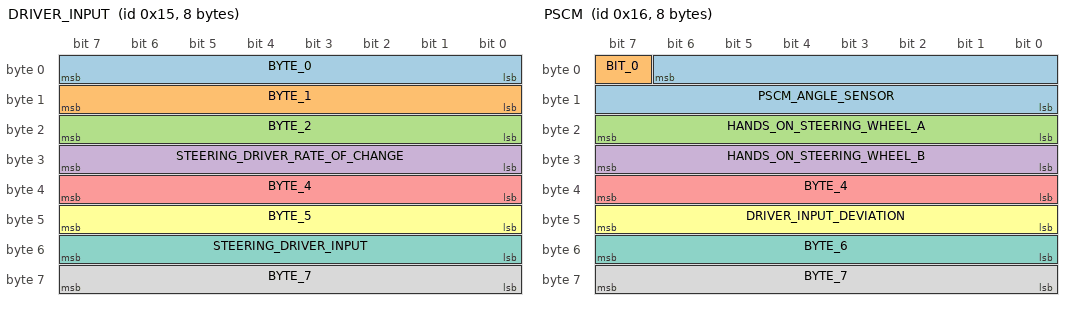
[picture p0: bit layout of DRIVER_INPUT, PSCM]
BO_ 21 DRIVER_INPUT: 8 XXX
 SG_ BYTE_0 : 7|8@0+ (1,0) [0|255] "" XXX
 SG_ BYTE_1 : 15|8@0+ (1,0) [0|255] "" XXX
 SG_ BYTE_2 : 16|8@1+ (1,0) [0|255] "" XXX
 SG_ STEERING_DRIVER_RATE_OF_CHANGE : 31|8@0- (1,0) [0|255] "" XXX
 SG_ BYTE_4 : 39|8@0+ (1,0) [0|255] "" XXX
 SG_ BYTE_5 : 40|8@1+ (1,0) [0|255] "" XXX
 SG_ STEERING_DRIVER_INPUT : 55|8@0- (1,1) [0|255] "" XXX
 SG_ BYTE_7 : 63|8@0+ (1,0) [0|255] "" XXX

BO_ 22 PSCM: 8 XXX
 SG_ PSCM_ANGLE_SENSOR : 6|15@0- (0.05596,0) [-916|916] "º" XXX
 SG_ BIT_0 : 7|1@0+ (1,0) [0|1] "" XXX
 SG_ HANDS_ON_STEERING_WHEEL_A : 23|8@0+ (1,0) [0|255] "" XXX
 SG_ HANDS_ON_STEERING_WHEEL_B : 31|8@0+ (1,0) [0|255] "" XXX
 SG_ BYTE_4 : 39|8@0+ (1,0) [0|255] "" XXX
 SG_ DRIVER_INPUT_DEVIATION : 47|8@0- (1,0) [-128|127] "" XXX
 SG_ BYTE_6 : 55|8@0+ (1,0) [0|255] "" XXX
 SG_ BYTE_7 : 63|8@0+ (1,0) [0|255] "" XXX

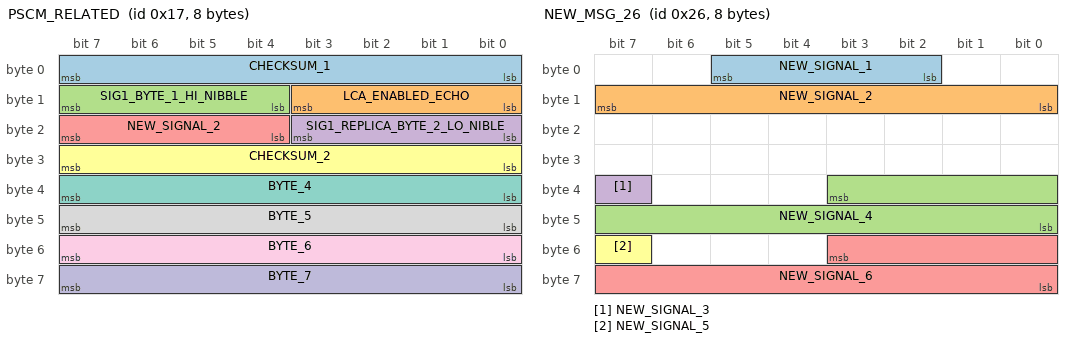
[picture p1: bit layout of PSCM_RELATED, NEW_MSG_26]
BO_ 23 PSCM_RELATED: 8 XXX
 SG_ CHECKSUM_1 : 7|8@0+ (1,0) [0|255] "" XXX
 SG_ LCA_ENABLED_ECHO : 11|4@0+ (1,0) [0|15] "" XXX
 SG_ SIG1_BYTE_1_HI_NIBBLE : 15|4@0+ (1,0) [0|15] "" XXX
 SG_ SIG1_REPLICA_BYTE_2_LO_NIBLE : 19|4@0+ (1,0) [0|15] "" XXX
 SG_ NEW_SIGNAL_2 : 23|4@0+ (1,0) [0|15] "" XXX
 SG_ CHECKSUM_2 : 31|8@0+ (1,0) [0|255] "" XXX
 SG_ BYTE_4 : 39|8@0+ (1,0) [0|255] "" XXX
 SG_ BYTE_5 : 47|8@0+ (1,0) [0|255] "" XXX
 SG_ BYTE_6 : 55|8@0+ (1,0) [0|255] "" XXX
 SG_ BYTE_7 : 63|8@0+ (1,0) [0|255] "" XXX

BO_ 26 NEW_MSG_1A: 8 XXX
 SG_ NEW_SIGNAL_2 : 5|1@0+ (1,0) [0|1] "" XXX
 SG_ NEW_SIGNAL_1 : 7|1@0+ (1,0) [0|1] "" XXX

BO_ 38 NEW_MSG_26: 8 XXX
 SG_ NEW_SIGNAL_1 : 5|4@0+ (1,0) [0|15] "" XXX
 SG_ NEW_SIGNAL_2 : 15|8@0+ (1,0) [0|255] "" XXX
 SG_ NEW_SIGNAL_4 : 35|12@0+ (1,0) [0|4095] "" XXX
 SG_ NEW_SIGNAL_3 : 39|1@0+ (1,0) [0|1] "" XXX
 SG_ NEW_SIGNAL_6 : 51|12@0+ (1,0) [0|4095] "" XXX
 SG_ NEW_SIGNAL_5 : 55|1@0+ (1,0) [0|1] "" XXX

BO_ 55 NEW_MSG_37: 8 XXX
 SG_ ACCELERATOR_PEDAL_RATE_OF_CHANGE : 6|15@0+ (1,0) [0|32767] "" XXX

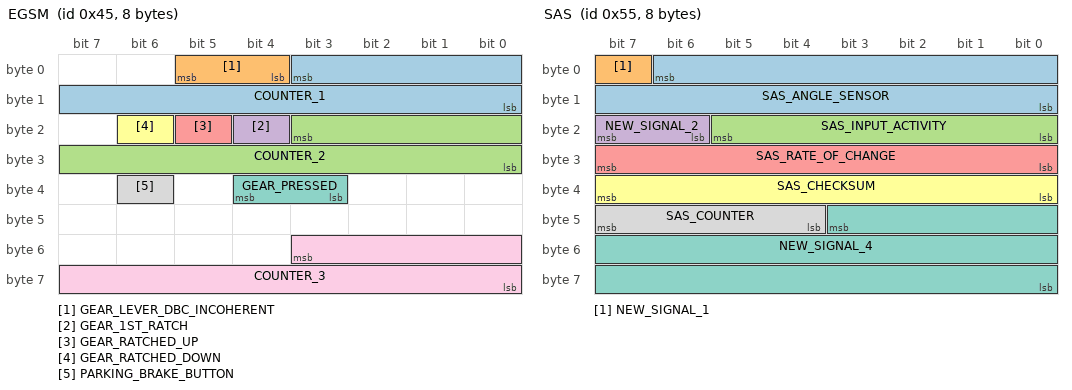
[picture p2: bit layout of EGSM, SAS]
BO_ 69 EGSM: 8 XXX
 SG_ COUNTER_1 : 3|12@0+ (1,0) [0|4095] "" XXX
 SG_ GEAR_LEVER_DBC_INCOHERENT : 5|2@0+ (1,0) [0|3] "" XXX
 SG_ COUNTER_2 : 19|12@0+ (1,0) [0|4095] "" XXX
 SG_ GEAR_1ST_RATCH : 20|1@0+ (1,0) [0|1] "" XXX
 SG_ GEAR_RATCHED_UP : 21|1@0+ (1,0) [0|1] "" XXX
 SG_ GEAR_RATCHED_DOWN : 22|1@0+ (1,0) [0|1] "" XXX
 SG_ GEAR_PRESSED : 36|2@0+ (1,0) [0|3] "" XXX
 SG_ PARKING_BRAKE_BUTTON : 38|1@0+ (1,0) [0|1] "" XXX
 SG_ COUNTER_3 : 51|12@0+ (1,0) [0|4095] "" XXX

BO_ 85 SAS: 8 XXX
 SG_ SAS_ANGLE_SENSOR : 6|15@0- (0.05596,0) [0|32767] "º" XXX
 SG_ NEW_SIGNAL_1 : 7|1@0+ (1,0) [0|1] "" XXX
 SG_ SAS_INPUT_ACTIVITY : 21|6@0+ (1,0) [0|16383] "" XXX
 SG_ NEW_SIGNAL_2 : 23|2@0+ (1,0) [0|3] "" XXX
 SG_ SAS_RATE_OF_CHANGE : 31|8@0- (1,0) [0|255] "" XXX
 SG_ SAS_CHECKSUM : 39|8@0+ (1,0) [0|4095] "" XXX
 SG_ NEW_SIGNAL_4 : 43|20@0+ (1,0) [0|1048575] "" XXX
 SG_ SAS_COUNTER : 44|4@1+ (1,0) [0|15] "" XXX

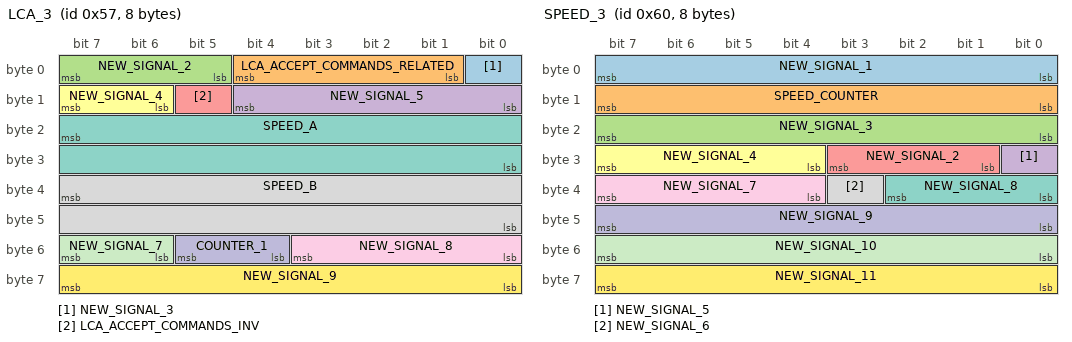
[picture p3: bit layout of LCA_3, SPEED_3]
BO_ 87 LCA_3: 8 XXX
 SG_ NEW_SIGNAL_3 : 0|1@0+ (1,0) [0|1] "" XXX
 SG_ LCA_ACCEPT_COMMANDS_RELATED : 4|4@0+ (1,0) [0|15] "" XXX
 SG_ NEW_SIGNAL_2 : 7|3@0+ (1,0) [0|7] "" XXX
 SG_ NEW_SIGNAL_5 : 12|5@0+ (1,0) [0|31] "" XXX
 SG_ LCA_ACCEPT_COMMANDS_INV : 13|1@0+ (1,0) [0|1] "" XXX
 SG_ NEW_SIGNAL_4 : 15|2@0+ (1,0) [0|3] "" XXX
 SG_ SPEED_A : 23|16@0+ (1,0) [0|65535] "" XXX
 SG_ SPEED_B : 39|16@0+ (1,0) [0|65535] "" XXX
 SG_ NEW_SIGNAL_8 : 51|4@0+ (1,0) [0|15] "" XXX
 SG_ COUNTER_1 : 53|2@0+ (1,0) [0|3] "" XXX
 SG_ NEW_SIGNAL_7 : 55|2@0+ (1,0) [0|3] "" XXX
 SG_ NEW_SIGNAL_9 : 63|8@0+ (1,0) [0|255] "" XXX

BO_ 88 LCA: 8 XXX
 SG_ NEW_SIGNAL_3 : 1|2@0+ (1,0) [0|3] "" XXX
 SG_ NEW_SIGNAL_8 : 2|1@0+ (1,0) [0|1] "" XXX
 SG_ LCA_ENABLE_INV : 3|1@0+ (1,0) [0|1] "" XXX
 SG_ NEW_SIGNAL_2 : 5|2@0+ (1,0) [0|3] "" XXX
 SG_ NEW_SIGNAL_1 : 7|2@0+ (1,0) [0|3] "" XXX
 SG_ LCA_STEER_LOOSELY_1 : 15|8@0+ (1,0) [0|255] "" XXX
 SG_ LCA_STEER_ACTIVE_INCOHERENT : 16|1@0+ (1,0) [0|1] "" XXX
 SG_ LCA_STEER_ACTIVE : 18|2@0+ (1,0) [0|3] "" XXX
 SG_ NEW_SIGNAL_7 : 21|3@0+ (1,0) [0|7] "" XXX
 SG_ NEW_SIGNAL_9 : 23|2@0+ (1,0) [0|3] "" XXX
 SG_ LCA_STEER_LOOSELY_2 : 31|8@0+ (1,0) [0|255] "" XXX
 SG_ NEW_SIGNAL_4 : 39|8@0+ (1,0) [0|255] "" XXX
 SG_ CURVE_RIGHT : 45|6@0+ (1,0) [0|63] "" XXX
 SG_ NEW_SIGNAL_5 : 46|2@1+ (1,0) [0|3] "" XXX
 SG_ LCA_STEER : 55|8@0+ (1,0) [0|255] "" XXX
 SG_ NEW_SIGNAL_10 : 59|4@0+ (1,0) [0|15] "" XXX
 SG_ NEW_SIGNAL_6 : 60|4@1+ (1,0) [0|15] "" XXX

BO_ 96 SPEED_3: 8 XXX
 SG_ NEW_SIGNAL_1 : 0|8@1+ (1,0) [0|255] "" XXX
 SG_ SPEED_COUNTER : 15|8@0+ (1,0) [0|255] "" XXX
 SG_ NEW_SIGNAL_3 : 23|8@0+ (1,0) [0|255] "" XXX
 SG_ NEW_SIGNAL_5 : 24|1@0+ (1,0) [0|1] "" XXX
 SG_ NEW_SIGNAL_2 : 27|3@0+ (1,0) [0|7] "" XXX
 SG_ NEW_SIGNAL_4 : 31|4@0+ (1,0) [0|15] "" XXX
 SG_ NEW_SIGNAL_8 : 34|3@0+ (1,0) [0|7] "" XXX
 SG_ NEW_SIGNAL_6 : 35|1@0+ (1,0) [0|1] "" XXX
 SG_ NEW_SIGNAL_7 : 39|4@0+ (1,0) [0|15] "" XXX
 SG_ NEW_SIGNAL_9 : 40|8@1+ (1,0) [0|255] "" XXX
 SG_ NEW_SIGNAL_10 : 55|8@0+ (1,0) [0|255] "" XXX
 SG_ NEW_SIGNAL_11 : 56|8@1+ (1,0) [0|255] "" XXX

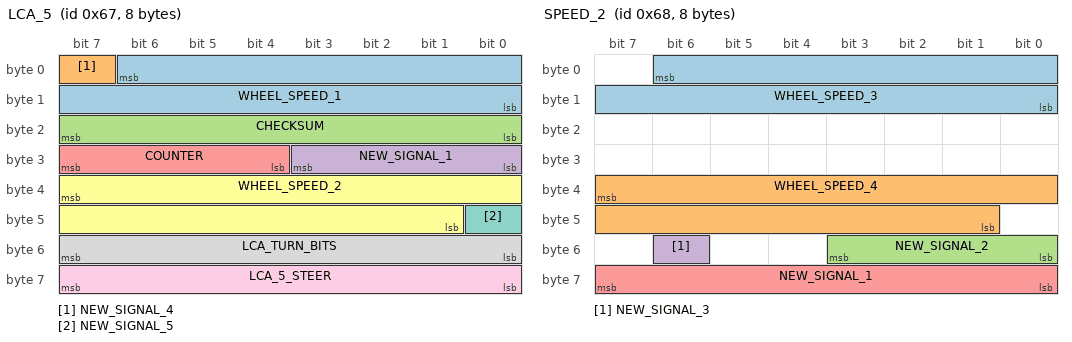
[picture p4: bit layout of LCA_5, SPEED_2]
BO_ 103 LCA_5: 8 XXX
 SG_ WHEEL_SPEED_1 : 6|15@0+ (0.1,0) [0|255] "rpm" XXX
 SG_ NEW_SIGNAL_4 : 7|1@0+ (1,0) [0|1] "" XXX
 SG_ CHECKSUM : 23|8@0+ (1,0) [0|4095] "" XXX
 SG_ NEW_SIGNAL_1 : 24|4@1+ (1,0) [0|15] "" XXX
 SG_ COUNTER : 28|4@1+ (1,0) [0|15] "" XXX
 SG_ WHEEL_SPEED_2 : 39|15@0+ (0.1,0) [0|32767] "rpm" XXX
 SG_ NEW_SIGNAL_5 : 40|1@0+ (1,0) [0|1] "" XXX
 SG_ LCA_TURN_BITS : 55|8@0+ (1,0) [0|255] "" XXX
 SG_ LCA_5_STEER : 63|8@0+ (1,0) [0|255] "" XXX

BO_ 104 SPEED_2: 8 XXX
 SG_ WHEEL_SPEED_3 : 6|15@0+ (0.1,0) [0|32767] "rpm" XXX
 SG_ WHEEL_SPEED_4 : 39|15@0+ (0.1,0) [0|32767] "rpm" XXX
 SG_ NEW_SIGNAL_2 : 51|4@0+ (1,0) [0|15] "" XXX
 SG_ NEW_SIGNAL_3 : 54|1@0+ (1,0) [0|1] "" XXX
 SG_ NEW_SIGNAL_1 : 56|8@1+ (1,0) [0|255] "" XXX

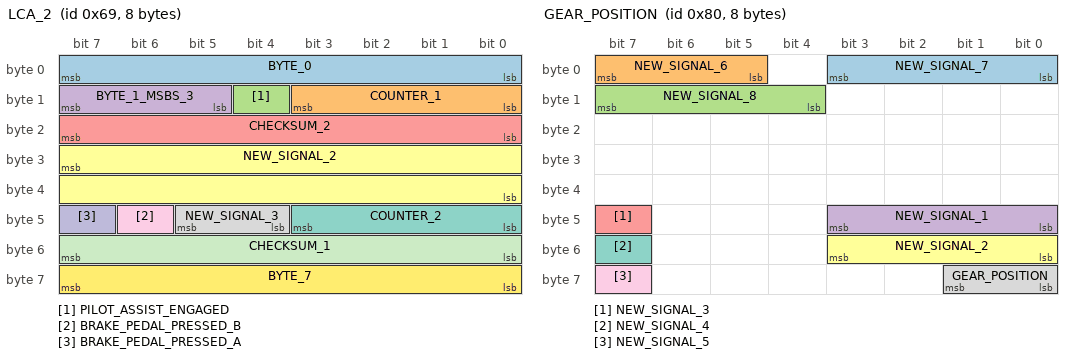
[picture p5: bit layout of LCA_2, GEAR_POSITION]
BO_ 105 LCA_2: 8 XXX
 SG_ BYTE_0 : 7|8@0+ (1,0) [0|2047] "" XXX
 SG_ COUNTER_1 : 11|4@0+ (1,0) [0|4095] "" XXX
 SG_ PILOT_ASSIST_ENGAGED : 12|1@0+ (1,0) [0|1] "" XXX
 SG_ BYTE_1_MSBS_3 : 15|3@0+ (1,0) [0|7] "" XXX
 SG_ CHECKSUM_2 : 23|8@0+ (1,0) [0|255] "" XXX
 SG_ NEW_SIGNAL_2 : 31|16@0+ (1,0) [0|65535] "" XXX
 SG_ COUNTER_2 : 43|4@0+ (1,0) [0|4095] "" XXX
 SG_ NEW_SIGNAL_3 : 45|2@0+ (1,0) [0|3] "" XXX
 SG_ BRAKE_PEDAL_PRESSED_B : 46|1@0+ (1,0) [0|1] "" XXX
 SG_ BRAKE_PEDAL_PRESSED_A : 47|1@0+ (-1,1) [0|1] "" XXX
 SG_ CHECKSUM_1 : 55|8@0+ (1,0) [0|255] "" XXX
 SG_ BYTE_7 : 63|8@0+ (1,0) [0|255] "" XXX

BO_ 112 BUS1_SPEED: 8 XXX
 SG_ BUS1_SPEED : 23|16@0+ (0.01886,0) [0|65535] "m/s" XXX

BO_ 128 GEAR_POSITION: 8 XXX
 SG_ NEW_SIGNAL_7 : 3|4@0+ (1,0) [0|15] "" XXX
 SG_ NEW_SIGNAL_6 : 7|3@0+ (1,0) [0|7] "" XXX
 SG_ NEW_SIGNAL_8 : 12|4@1+ (1,0) [0|15] "" XXX
 SG_ NEW_SIGNAL_1 : 43|4@0+ (1,0) [0|15] "" XXX
 SG_ NEW_SIGNAL_3 : 47|1@0+ (1,0) [0|1] "" XXX
 SG_ NEW_SIGNAL_2 : 48|4@1+ (1,0) [0|15] "" XXX
 SG_ NEW_SIGNAL_4 : 55|1@0+ (1,0) [0|1] "" XXX
 SG_ GEAR_POSITION : 57|2@0+ (1,0) [0|3] "" XXX
 SG_ NEW_SIGNAL_5 : 63|1@0+ (1,0) [0|1] "" XXX

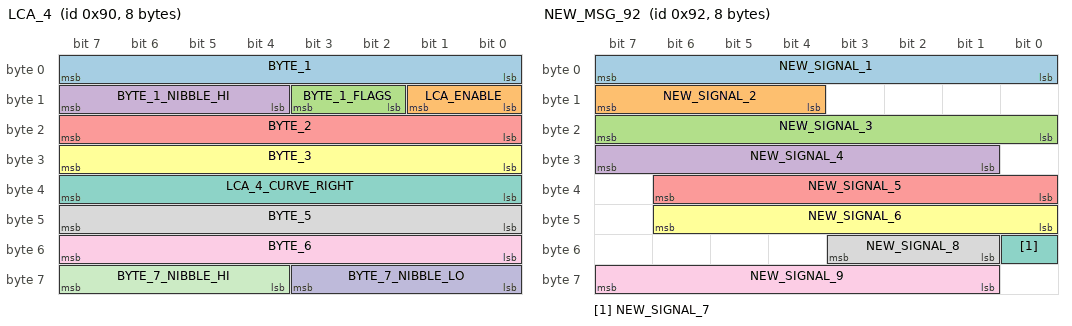
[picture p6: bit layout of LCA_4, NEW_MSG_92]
BO_ 144 LCA_4: 8 XXX
 SG_ BYTE_1 : 7|8@0+ (1,0) [0|16383] "" XXX
 SG_ LCA_ENABLE : 9|2@0+ (1,0) [0|3] "" XXX
 SG_ BYTE_1_FLAGS : 11|2@0+ (1,0) [0|3] "" XXX
 SG_ BYTE_1_NIBBLE_HI : 15|4@0+ (1,0) [0|63] "" XXX
 SG_ BYTE_2 : 23|8@0+ (1,0) [0|255] "" XXX
 SG_ BYTE_3 : 31|8@0+ (1,0) [0|255] "" XXX
 SG_ LCA_4_CURVE_RIGHT : 39|8@0+ (1,0) [0|255] "" XXX
 SG_ BYTE_5 : 47|8@0- (1,0) [0|255] "" XXX
 SG_ BYTE_6 : 48|8@1+ (1,0) [0|255] "" XXX
 SG_ BYTE_7_NIBBLE_LO : 59|4@0+ (1,0) [0|15] "" XXX
 SG_ BYTE_7_NIBBLE_HI : 60|4@1+ (1,0) [0|15] "" XXX

BO_ 146 NEW_MSG_92: 8 XXX
 SG_ NEW_SIGNAL_1 : 7|8@0+ (1,0) [0|255] "" XXX
 SG_ NEW_SIGNAL_2 : 12|4@1+ (1,0) [0|15] "" XXX
 SG_ NEW_SIGNAL_3 : 23|8@0+ (1,0) [0|255] "" XXX
 SG_ NEW_SIGNAL_4 : 25|7@1+ (1,0) [0|127] "" XXX
 SG_ NEW_SIGNAL_5 : 38|7@0+ (1,0) [0|127] "" XXX
 SG_ NEW_SIGNAL_6 : 40|7@1+ (1,0) [0|127] "" XXX
 SG_ NEW_SIGNAL_7 : 48|1@0+ (1,0) [0|1] "" XXX
 SG_ NEW_SIGNAL_8 : 49|3@1+ (1,0) [0|7] "" XXX
 SG_ NEW_SIGNAL_9 : 57|7@1+ (1,0) [0|127] "" XXX

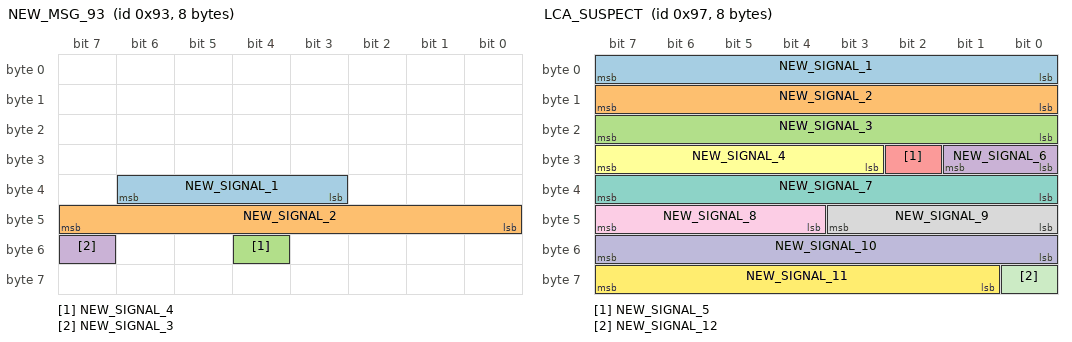
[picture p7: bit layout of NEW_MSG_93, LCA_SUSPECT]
BO_ 147 NEW_MSG_93: 8 XXX
 SG_ NEW_SIGNAL_1 : 38|4@0+ (1,0) [0|15] "" XXX
 SG_ NEW_SIGNAL_2 : 47|8@0+ (1,0) [0|255] "" XXX
 SG_ NEW_SIGNAL_4 : 52|1@0+ (1,0) [0|1] "" XXX
 SG_ NEW_SIGNAL_3 : 55|1@0+ (1,0) [0|1] "" XXX

BO_ 151 LCA_SUSPECT: 8 XXX
 SG_ NEW_SIGNAL_1 : 7|8@0+ (1,0) [0|255] "" XXX
 SG_ NEW_SIGNAL_2 : 8|8@1+ (1,0) [0|255] "" XXX
 SG_ NEW_SIGNAL_3 : 23|8@0+ (1,0) [0|255] "" XXX
 SG_ NEW_SIGNAL_6 : 25|2@0+ (1,0) [0|3] "" XXX
 SG_ NEW_SIGNAL_5 : 26|1@0+ (1,0) [0|1] "" XXX
 SG_ NEW_SIGNAL_4 : 27|5@1+ (1,0) [0|31] "" XXX
 SG_ NEW_SIGNAL_7 : 39|8@0+ (1,0) [0|255] "" XXX
 SG_ NEW_SIGNAL_9 : 43|4@0+ (1,0) [0|15] "" XXX
 SG_ NEW_SIGNAL_8 : 44|4@1+ (1,0) [0|15] "" XXX
 SG_ NEW_SIGNAL_10 : 48|8@1+ (1,0) [0|255] "" XXX
 SG_ NEW_SIGNAL_12 : 56|1@0+ (1,0) [0|1] "" XXX
 SG_ NEW_SIGNAL_11 : 63|7@0+ (1,0) [0|127] "" XXX

BO_ 336 NEW_MSG_150: 8 XXX
 SG_ IGN_DRAFT : 5|2@0+ (1,0) [0|3] "" XXX

BO_ 341 NEW_MSG_155: 8 XXX
 SG_ NEW_SIGNAL_1 : 23|8@0+ (1,0) [0|255] "" XXX

BO_ 592 ECM_1: 8 XXX
 SG_ ACCELERATOR_PEDAL_POS : 31|8@0+ (1,0) [0|255] "" XXX

BO_ 773 NEW_MSG_305: 8 XXX
 SG_ NEW_SIGNAL_1 : 23|8@0+ (1,0) [0|255] "" XXX

BO_ 778 NEW_MSG_30A: 8 XXX
 SG_ NEW_SIGNAL_1 : 15|8@0+ (1,0) [0|255] "" XXX

BO_ 832 BUS1_CRUISE_CONTROL: 8 XXX
 SG_ CRUISE_CONTROL_ENABLED : 56|1@0+ (1,0) [0|1] "" XXX
 SG_ CRUISE_CONTROL_ENABLED_IDLE_TRAFFIC : 57|1@0+ (1,0) [0|1] "" XXX

BO_ 896 NEW_MSG_380: 8 XXX
 SG_ NEW_SIGNAL_1 : 23|8@0+ (1,0) [0|255] "" XXX

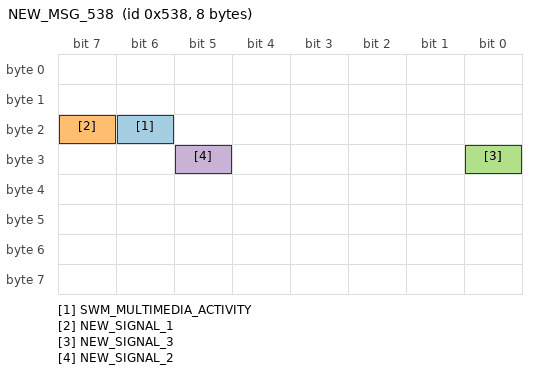
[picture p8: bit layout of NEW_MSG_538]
BO_ 1336 NEW_MSG_538: 8 XXX
 SG_ SWM_MULTIMEDIA_ACTIVITY : 22|1@0+ (1,0) [0|1] "" XXX
 SG_ NEW_SIGNAL_1 : 23|1@0+ (1,0) [0|1] "" XXX
 SG_ NEW_SIGNAL_3 : 24|1@0+ (1,0) [0|1] "" XXX
 SG_ NEW_SIGNAL_2 : 29|1@0+ (1,0) [0|1] "" XXX

CM_ BO_ 23 "Might be related to PSCM 0x16";
CM_ SG_ 87 LCA_ACCEPT_COMMANDS_RELATED "Goes to 15 when actively operating LCA";
CM_ SG_ 87 LCA_ACCEPT_COMMANDS_INV "Goes to 0 when PSCM allowed to receive LCA commands";
CM_ SG_ 87 NEW_SIGNAL_9 "NEW_SIGNAL_9 appears to be similar to LCA_5_STEER, but different scale, and zero-point is at 128. I haven't seen what happens once LCA_TURN_BITS wrap";
CM_ SG_ 88 LCA_ENABLE_INV "Master enable, active-low";
CM_ SG_ 88 CURVE_RIGHT "Only appears to be HIGH on curve right, LOW curve left";
CM_ SG_ 88 LCA_STEER "Seems torque-based, signed, follows the road curvature";
CM_ SG_ 103 WHEEL_SPEED_1 "Possible Front Left  (FL)";
CM_ SG_ 103 WHEEL_SPEED_2 "Possible Front Right (FR)";
CM_ SG_ 103 LCA_TURN_BITS "Two-byte torque encoding (high byte). Left: 128->134 (increments), Right: 255->249 (decrements), Neutral: 186";
CM_ SG_ 103 LCA_5_STEER "Two-byte torque encoding (low byte). Left: 0->255 (wraps at boundary), Right: 255->0 (wraps at boundary)";
CM_ SG_ 104 WHEEL_SPEED_3 "Possible Rear Left (RR)";
CM_ SG_ 104 WHEEL_SPEED_4 "Possibe Rear Right (RR)";
CM_ SG_ 144 LCA_4_CURVE_RIGHT "Curve  URVE_RIGHT 1:1";
CM_ SG_ 144 BYTE_5 "Seems to increase/correlate on curves, even when LCA off";
CM_ SG_ 592 ACCELERATOR_PEDAL_POS "Full gas ~200; Idle ~20";
